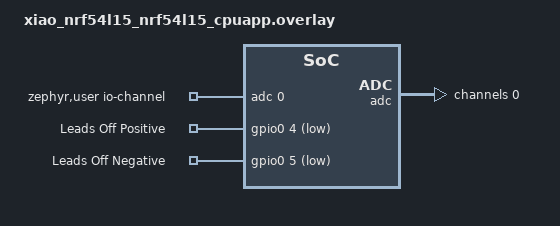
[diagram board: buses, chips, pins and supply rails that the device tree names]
/ {
	aliases {
		leads_pos = &leads_off_pos;
		leads_negative = &leads_off_negative;

	};
	zephyr,user {
		io-channels = <&adc 0>;
	};

	leads_off {
		compatible = "gpio-keys";
		leads_off_pos: d1{
			gpios = <&gpio0 4 (GPIO_PULL_UP | GPIO_ACTIVE_LOW)>;
			label = "Leads Off Positive";
		};
		leads_off_negative: d2 {
			gpios = <&gpio0 5 (GPIO_PULL_UP | GPIO_ACTIVE_LOW)>;
			label = "Leads Off Negative";
		};
	};
};

&adc {
	status = "okay";
	#address-cells = <1>;
	#size-cells = <0>;

	channel@0 {
		reg = <0>;
		zephyr,gain = "ADC_GAIN_1_6";
		zephyr,reference = "ADC_REF_INTERNAL";
		zephyr,acquisition-time = <ADC_ACQ_TIME_DEFAULT>;
		zephyr,resolution = <12>;
	};
};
